# LPC13xx register map
File version: 1
CPU: 
Registers are 32-bit, read-write, reset 0x0 unless marked. A register's access mark holds for its fields unless they carry their own. Offsets are from the block's base; lines under a group give offsets from that group; [hi:lo] are bit positions; {n}, {i} and the like mark numbered series; 'fields as' and 'values as' point back to an identical list; <NAME> marks a mode.

## Memory map
0x40000000 I2C size 0xFFF — Product name title=UM10375 Chapter title=LPC13xx I2C-bus controller Modification date=4/19/2011 Major revision=2 Minor revision=1
0x40004000 WWDT size 0xFFF — Product name title=UM10375 Chapter title=LPC13xx Windowed WatchDog Timer (WWDT) Modification date=4/19/2011 Major revision=2 Minor revision=1
0x40008000 UART size 0xFFF — Product name title=UM10375 Chapter title=LPC13xx UART Modification date=4/19/2011 Major revision=2 Minor revision=1
0x4000C000 CT16B0 size 0xFFF — Product name title=UM10375 Chapter title=LPC13xx 16-bit timer/counters (CT16B0/1) Modification date=4/19/2011 Major revision=2 Minor revision=1
0x40010000 CT16B1 size 0xFFF — Product name title=UM10375 Chapter title=LPC13xx 16-bit timer/counters (CT16B0/1) Modification date=4/19/2011 Major revision=2 Minor revision=1
0x40014000 CT32B0 size 0xFFF — Product name title=UM10375 Chapter title=LPC13xx 32-bit timer/counters (CT32B0/1) Modification date=4/19/2011 Major revision=2 Minor revision=1
0x40018000 CT32B1 size 0xFFF — Product name title=UM10375 Chapter title=LPC13xx 32-bit timer/counters (CT32B0/1) Modification date=4/19/2011 Major revision=2 Minor revision=1
0x4001C000 ADC size 0xFFF — Product name title=UM10375 Chapter title=LPC13xx Analog-to-Digital Converter (ADC) Modification date=4/19/2011 Major revision=2 Minor revision=1
0x40020000 USB size 0xFFF — Product name title=UM10375 Chapter title=LPC13xx USB device controller Modification date=4/20/2011 Major revision=2 Minor revision=1
0x40038000 PMU size 0xFFF — Product name title=UM10375 Chapter title=LPC13xx Power Management Unit (PMU) Modification date=4/20/2011 Major revision=2 Minor revision=1
0x4003C000 FMC size 0xFFF — Product name title=UM10375 Chapter title=LPC13xx Flash memory programming firmware Modification date=4/20/2011 Major revision=2 Minor revision=1
0x40040000 SSP0 size 0xFFF — Product name title=UM10375 Chapter title=LPC13xx SSP0/1 Modification date=4/20/2011 Major revision=2 Minor revision=1
0x40044000 IOCON size 0xFFF — Product name title=UM10375 Chapter title=LPC13xx I/O configuration Modification date=4/20/2011 Major revision=2 Minor revision=1
0x40048000 SYSCON size 0xFFF — Product name title=UM10375 Chapter title=LPC13xx System configuration Modification date=4/4/2011 Major revision=2 Minor revision=2
0x40058000 SSP1 size 0xFFF — Product name title=UM10375 Chapter title=LPC13xx SSP0/1 Modification date=4/20/2011 Major revision=2 Minor revision=1
0x50000000 GPIO0 size 0xFFFFF — Product name title=UM10375 Chapter title=LPC13xx General Purpose I/O (GPIO) Modification date=4/20/2011 Major revision=2 Minor revision=1
0x50010000 GPIO1 size 0xFFFFF — Product name title=UM10375 Chapter title=LPC13xx General Purpose I/O (GPIO) Modification date=4/20/2011 Major revision=2 Minor revision=1
0x50020000 GPIO2 size 0xFFFFF — Product name title=UM10375 Chapter title=LPC13xx General Purpose I/O (GPIO) Modification date=4/20/2011 Major revision=2 Minor revision=1
0x50030000 GPIO3 size 0xFFFFF — Product name title=UM10375 Chapter title=LPC13xx General Purpose I/O (GPIO) Modification date=4/20/2011 Major revision=2 Minor revision=1

## Interrupts
{n} PIO0_{n} (SYSCON) (n=0..11)
{n+12} PIO1_{n} (SYSCON) (n=0..11)
{n+24} PIO2_{n} (SYSCON) (n=0..11)
36 PIO3_0 (SYSCON)
37 PIO3_1 (SYSCON)
38 PIO3_2 (SYSCON)
39 PIO3_3 (SYSCON)
40 I2C0 (I2C)
41 CT16B0
42 CT16B1
43 CT32B0
44 CT32B1
45 SSP0
46 UART
47 USBIRQ (USB)
48 USBFIQ (USB)
49 ADC
50 WDT (WWDT)
51 BOD (SYSCON)
53 PIO_3 (GPIO3)
54 PIO_2 (GPIO2)
55 PIO_1 (GPIO1)
56 PIO_0 (GPIO0)
57 SSP1

## WWDT — Product name title=UM10375 Chapter title=LPC13xx Windowed WatchDog Timer (WWDT) Modification date=4/19/2011 Major revision=2 Minor revision=1
Base 0x40004000
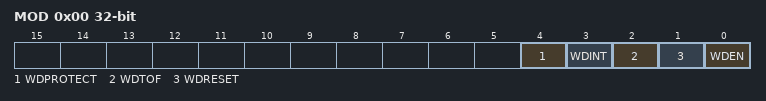
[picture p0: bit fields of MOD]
0x00 MOD — Watchdog mode register. This register contains the basic mode and status of the Watchdog Timer.
  [4] WDPROTECT — Watchdog update mode. This bit is Set Only.
    0=ANYTIME (The watchdog reload value (WDTC) can be changed at any time.); 1=MATCH (The watchdog reload value (WDTC) can be changed only after the counter is below the value of WDWARNINT and WDWINDOW. Note: this mode is intended for use only when WDRESET =1.)
  [3] WDINT — Watchdog interrupt flag. Set when the timer reaches the value in WDWARNINT. Cleared by software.
  [2] WDTOF — Watchdog time-out flag. Set when the watchdog timer times out, by a feed error, or by events associated with WDPROTECT, cleared by software. Causes a chip reset if WDRESET = 1.
  [1] WDRESET — Watchdog reset enable bit. This bit is Set Only.
    0=RESET (A watchdog timeout will not cause a chip reset.); 1=INTERRUPT (A watchdog timeout will cause a chip reset.)
  [0] WDEN — Watchdog enable bit. This bit is Set Only. Remark: Setting this bit to one also locks the watchdog clock source. Once the watchdog timer is enabled, the watchdog timer clock source cannot be changed. If the watchdog timer is needed in Deep-sleep mode, the watchdog clock source must be changed to watchdog oscillator before setting this bit to one.
    0=STOP (The watchdog timer is stopped.); 1=RUN (The watchdog timer is running.)
0x04 TC reset 0xFF — Watchdog timer constant register. This register determines the time-out value.
  [23:0] Count — Watchdog time-out interval.
0x08 FEED wo reset not defined — Watchdog feed sequence register. Writing 0xAA followed by 0x55 to this register reloads the Watchdog timer with the value contained in WDTC.
  [7:0] Feed — Feed value should be 0xAA followed by 0x55.
0x0C TV ro reset 0xFF — Watchdog timer value register. This register reads out the current value of the Watchdog timer.
  [23:0] Count — Counter timer value.
0x14 WARNINT — Watchdog Warning Interrupt compare value.
  [9:0] WARNINT — Watchdog warning interrupt compare value.
0x18 WINDOW reset 0xFFFFFF — Watchdog Window compare value.
  [23:0] WINDOW — Watchdog window value.
